# uart_registers: IP-XACT component
VLNV pulp-platform.org:peripheral.logic:uart_registers:1.0
Contains glue logic from apb_uart.

## Parameters
APB_ADDR_WIDTH = 12
TX_FIFO_DEPTH = 16

## Bus interfaces (logical=physical port)
apb: slave amba.com:AMBA3:APB:r1p0_4, memory map UART
  PADDR=PADDR, PSELx[0:0]=PSEL[0:0], PENABLE[0:0]=PENABLE[0:0], PWRITE[0:0]=PWRITE[0:0], PWDATA=PWDATA, PRDATA=PRDATA, PREADY=PREADY, PSLVERR=PSLVERR
fifo_rx: system pulp-platform.org:interface:fifo:1.0
  DATA_VALID=fifo_rx_valid, DATA=fifo_rx_data, FIFO_READY=fifo_rx_ready
fifo_tx: system pulp-platform.org:interface:fifo:1.0
  DATA=fifo_tx_data, DATA_VALID=fifo_tx_valid

## Ports
in clk
in rst_n
out trigger_level_q[1:0]
in tx_elements[$clog2(TX_FIFO_DEPTH):0]
out tx_fifo_clr_q
out rx_fifo_clr_q
out fifo_tx_data[7:0]
out fifo_tx_valid
in tx_ready
in fifo_rx_valid
in fifo_rx_data[8:0]
out fifo_rx_ready
out clr_int[3:0]
out cfg_div_o[15:0]
out cfg_stop_bits_o
out cfg_parity_en_o
out cfg_bits_o[1:0]
in PADDR[APB_ADDR_WIDTH-1:0]
in PENABLE
in PWDATA[31:0]
in PWRITE
in PSEL
out PRDATA[31:0]
out PREADY
out PSLVERR
out IER_o[2:0]
out RDA_o
in IIR_i
out error_int

## Address spaces and blocks
UART.uart_registers: base 'h0, range 8, width 8

## Registers
Registers are 8-bit, access not given, no defined reset value unless marked. A register's access mark holds for its fields unless they carry their own. Offsets are from the block's base; lines under a group give offsets from that group; [hi:lo] are bit positions; {n}, {i} and the like mark numbered series; 'fields as' and 'values as' point back to an identical list; <NAME> marks a mode.

## UART.uart_registers
Base 0x00000000
0x00 THR_RBR_DLL
  [7:0] Variant
0x01 IER_DLH
  [7:0] Variant
0x02 IIR_FCR
  [7:0] Variant
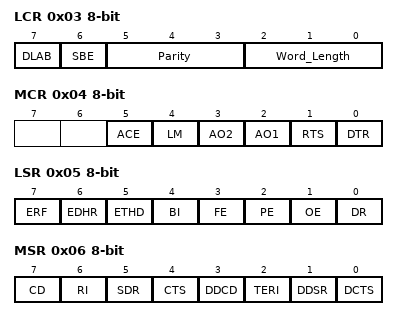
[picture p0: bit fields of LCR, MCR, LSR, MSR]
0x03 LCR
  [7] DLAB, [6] SBE, [5:3] Parity, [2:0] Word_Length
0x04 MCR
  [5] ACE, [4] LM, [3] AO2, [2] AO1, [1] RTS, [0] DTR
0x05 LSR
  [7] ERF, [6] EDHR, [5] ETHD, [4] BI, [3] FE, [2] PE, [1] OE, [0] DR
0x06 MSR
  [7] CD, [6] RI, [5] SDR, [4] CTS, [3] DDCD, [2] TERI, [1] DDSR, [0] DCTS
0x07 SR
